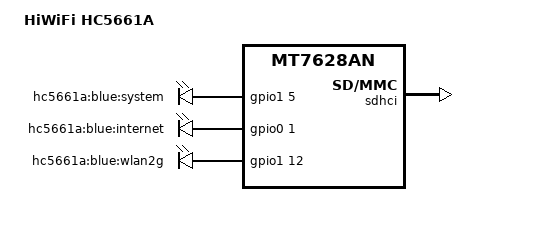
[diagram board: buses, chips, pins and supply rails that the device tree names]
/dts-v1/;

#include "mt7628an_hiwifi_hc5x61a.dtsi"

/ {
	compatible = "hiwifi,hc5661a", "mediatek,mt7628an-soc";
	model = "HiWiFi HC5661A";

	leds {
		compatible = "gpio-leds";

		led_system: system {
			label = "hc5661a:blue:system";
			gpios = <&gpio1 5 GPIO_ACTIVE_HIGH>;
		};

		internet {
			label = "hc5661a:blue:internet";
			gpios = <&gpio0 1 GPIO_ACTIVE_HIGH>;
		};

		wlan2g {
			label = "hc5661a:blue:wlan2g";
			gpios = <&gpio1 12 GPIO_ACTIVE_HIGH>;
			linux,default-trigger = "phy0tpt";
		};
	};
};

&pinctrl {
	sdxc_router_pins: sdxc_router_mode {
		gpio {
			ralink,group = "i2s", "sdmode", "uart1", "gpio";
			ralink,function = "gpio";
		};

		esdmode {
			ralink,group = "esdmode";
			ralink,function = "sdxc";
		};
	};

	state_default: pinctrl0 {
		gpio {
			ralink,group = "i2c", "refclk", "wdt", "wled_an";
			ralink,function = "gpio";
		};
	};
};

&sdhci {
	status = "okay";
	pinctrl-0 = <&sdxc_router_pins>;
};

&ehci {
	status = "disabled";
};

&ohci {
	status = "disabled";
};
